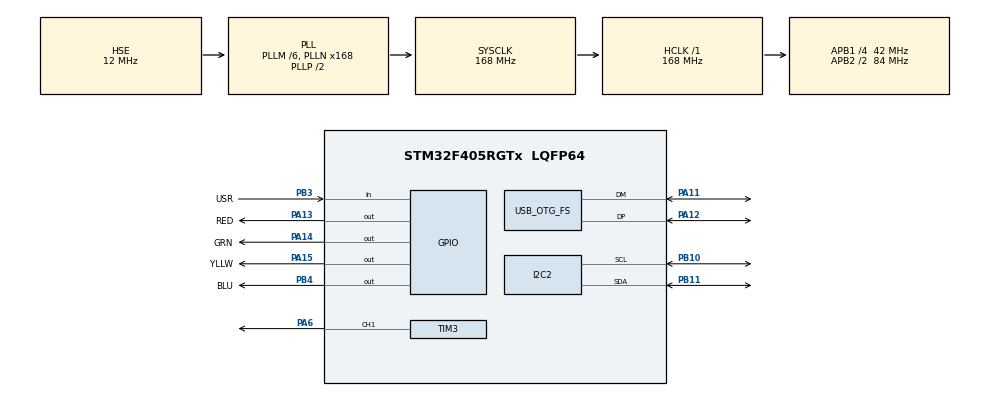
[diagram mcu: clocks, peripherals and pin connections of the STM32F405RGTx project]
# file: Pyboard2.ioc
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I2C2.I2C_Mode=I2C_Fast
Mcu.Family=STM32F4
Mcu.Name=STM32F405RGTx
Mcu.Package=LQFP64
NVIC.OTG_FS_IRQn=true\:0\:0\:false\:false\:true\:false\:true
NVIC.PriorityGroup=NVIC_PRIORITYGROUP_4
PA11.Mode=Device_Only
PA11.Signal=USB_OTG_FS_DM
PA12.Mode=Device_Only
PA12.Signal=USB_OTG_FS_DP
PA13.GPIO_Label=RED
PA13.GPIO_PuPd=GPIO_PULLDOWN
PA13.Signal=GPIO_Output
PA14.GPIO_Label=GRN
PA14.GPIO_PuPd=GPIO_PULLDOWN
PA14.Signal=GPIO_Output
PA15.GPIO_Label=YLLW
PA15.GPIO_PuPd=GPIO_PULLDOWN
PA15.GPIO_Speed=GPIO_SPEED_FREQ_LOW
PA15.PinState=GPIO_PIN_SET
PA15.Signal=GPIO_Output
PA6.Signal=S_TIM3_CH1
PB10.Mode=I2C
PB10.Signal=I2C2_SCL
PB11.Mode=I2C
PB11.Signal=I2C2_SDA
PB3.GPIO_Label=USR
PB3.GPIO_PuPd=GPIO_PULLUP
PB3.Signal=GPIO_Input
PB4.GPIO_Label=BLU
PB4.GPIO_PuPd=GPIO_PULLDOWN
PB4.Signal=GPIO_Output
PH0-OSC_IN.Mode=HSE-External-Oscillator
PH0-OSC_IN.Signal=RCC_OSC_IN
PH1-OSC_OUT.Mode=HSE-External-Oscillator
PH1-OSC_OUT.Signal=RCC_OSC_OUT
ProjectManager.HeapSize=0x200
ProjectManager.StackSize=0x400
ProjectManager.TargetToolchain=Makefile
RCC.48MHZClocksFreq_Value=48000000
RCC.AHBFreq_Value=168000000
RCC.APB1CLKDivider=RCC_HCLK_DIV4
RCC.APB1Freq_Value=42000000
RCC.APB1TimFreq_Value=84000000
RCC.APB2CLKDivider=RCC_HCLK_DIV2
RCC.APB2Freq_Value=84000000
RCC.APB2TimFreq_Value=168000000
RCC.CortexFreq_Value=168000000
RCC.HCLKFreq_Value=168000000
RCC.HSE_VALUE=12000000
RCC.HSI_VALUE=16000000
RCC.LSE_Timout=5000
RCC.LSE_VALUE=32768
RCC.PLLM=6
RCC.PLLN=168
RCC.PLLQ=7
RCC.RCC_MCO1Source=RCC_MCO1SOURCE_HSE
RCC.RCC_MCODiv2=RCC_MCODIV_3
RCC.SYSCLKFreq_VALUE=168000000
RCC.SYSCLKSource=RCC_SYSCLKSOURCE_PLLCLK
RCC.VCOOutputFreq_Value=336000000
SH.S_TIM3_CH1.0=TIM3_CH1,PWM Generation1 CH1
TIM3.AutoReloadPreload=TIM_AUTORELOAD_PRELOAD_ENABLE
TIM3.Channel-PWM\ Generation1\ CH1=TIM_CHANNEL_1
TIM3.Period=19999
TIM3.Prescaler=71
USB_DEVICE.CLASS_NAME_FS=CDC
USB_DEVICE.VirtualMode-CDC_FS=Cdc
USB_DEVICE.VirtualModeFS=Cdc_FS
USB_OTG_FS.VirtualMode=Device_Only
VP_TIM3_VS_ClockSourceINT.Mode=Internal
VP_USB_DEVICE_VS_USB_DEVICE_CDC_FS.Mode=CDC_FS
board=custom

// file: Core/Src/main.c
/* USER CODE BEGIN Header */
/**
  ******************************************************************************
  * @file           : main.c
  * @brief          : Main program body
  ******************************************************************************
  * @attention
  *
  * <h2><center>&copy; Copyright (c) 2020 STMicroelectronics.
  * All rights reserved.</center></h2>
  *
  * This software component is licensed by ST under Ultimate Liberty license
  * SLA0044, the "License"; You may not use this file except in compliance with
  * the License. You may obtain a copy of the License at:
  *                             www.st.com/SLA0044
  *
  ******************************************************************************
  */
/* USER CODE END Header */
#include "main.h"
#include "i2c.h"
#include "tim.h"
#include "usb_device.h"
#include "gpio.h"

/* USER CODE BEGIN Includes */

#include "usbd_cdc_if.h"
#include <string.h>
#include <stdlib.h>
#include "run.h"

/* USER CODE END Includes */

void SystemClock_Config(void);

int main(void)
{

  /* MCU Configuration--------------------------------------------------------*/

  /* Reset of all peripherals, Initializes the Flash interface and the Systick. */
  HAL_Init();

  /* Configure the system clock */
  SystemClock_Config();

  /* Initialize all configured peripherals */
  MX_GPIO_Init();
  MX_USB_DEVICE_Init();
  MX_I2C2_Init();
  MX_TIM3_Init();
  /* USER CODE BEGIN 2 */

  setup();

  /* USER CODE END 2 */

  /* Infinite loop */
  /* USER CODE BEGIN WHILE */
  while (1)
  {

    loop();
    /* USER CODE END WHILE */

  }
}

void SystemClock_Config(void)
{
  RCC_OscInitTypeDef RCC_OscInitStruct = {0};
  RCC_ClkInitTypeDef RCC_ClkInitStruct = {0};

  /** Configure the main internal regulator output voltage
  */
  __HAL_RCC_PWR_CLK_ENABLE();
  __HAL_PWR_VOLTAGESCALING_CONFIG(PWR_REGULATOR_VOLTAGE_SCALE1);
  /** Initializes the RCC Oscillators according to the specified parameters
  * in the RCC_OscInitTypeDef structure.
  */
  RCC_OscInitStruct.OscillatorType = RCC_OSCILLATORTYPE_HSE;
  RCC_OscInitStruct.HSEState = RCC_HSE_ON;
  RCC_OscInitStruct.PLL.PLLState = RCC_PLL_ON;
  RCC_OscInitStruct.PLL.PLLSource = RCC_PLLSOURCE_HSE;
  RCC_OscInitStruct.PLL.PLLM = 6;
  RCC_OscInitStruct.PLL.PLLN = 168;
  RCC_OscInitStruct.PLL.PLLP = RCC_PLLP_DIV2;
  RCC_OscInitStruct.PLL.PLLQ = 7;
  if (HAL_RCC_OscConfig(&RCC_OscInitStruct) != HAL_OK)
  {
    Error_Handler();
  }
  /** Initializes the CPU, AHB and APB buses clocks
  */
  RCC_ClkInitStruct.ClockType = RCC_CLOCKTYPE_HCLK|RCC_CLOCKTYPE_SYSCLK
                              |RCC_CLOCKTYPE_PCLK1|RCC_CLOCKTYPE_PCLK2;
  RCC_ClkInitStruct.SYSCLKSource = RCC_SYSCLKSOURCE_PLLCLK;
  RCC_ClkInitStruct.AHBCLKDivider = RCC_SYSCLK_DIV1;
  RCC_ClkInitStruct.APB1CLKDivider = RCC_HCLK_DIV4;
  RCC_ClkInitStruct.APB2CLKDivider = RCC_HCLK_DIV2;

  if (HAL_RCC_ClockConfig(&RCC_ClkInitStruct, FLASH_LATENCY_5) != HAL_OK)
  {
    Error_Handler();
  }
}

/* USER CODE BEGIN 4 */

I2C_HandleTypeDef* I2C2_Handler (void) { return &hi2c2; }

/* USER CODE END 4 */

void Error_Handler(void)
{
  __disable_irq();
  while (1)
  {
  }
}

/************************ (C) COPYRIGHT STMicroelectronics *****END OF FILE****/
